# XMC1300 register map
Vendor: Infineon; File version: 1.3.0 (Reference Manual v1.3)
CPU: CM0 r0p0, little endian, no MPU, no FPU, 2 interrupt priority bits
Registers are 32-bit, read-write, reset 0x0 unless marked. A register's access mark holds for its fields unless they carry their own. Offsets are from the block's base; [hi:lo] are bit positions; {n}, {i} and the like mark numbered series.

## ERU0 — Event Request Unit 0
Base 0x40010600
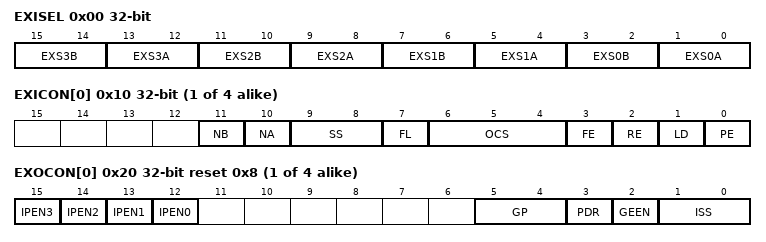
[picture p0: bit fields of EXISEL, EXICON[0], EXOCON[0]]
0x00 EXISEL — Event Input Select
  [4n+3:4n+2] EXS{n}B (n=0..3) — Event Source Select for B{n} (ERS{n})
    {v}=Input ERU_{n}B{v} is selected (v=0..3)
  [4n+1:4n] EXS{n}A (n=0..3) — Event Source Select for A{n} (ERS{n})
    {v}=Input ERU_{n}A{v} is selected (v=0..3)
{0x10+4i} EXICON[{i}] (i=0..3) — Event Input Control
  [11] NB — Input B Negation Select for ERSx
    0=Input B is used directly; 1=Input B is inverted
  [10] NA — Input A Negation Select for ERSx
    0=Input A is used directly; 1=Input A is inverted
  [9:8] SS — Input Source Select for ERSx
    0=Input A without additional combination; 1=Input B without additional combination; 2=Input A OR input B; 3=Input A AND input B
  [7] FL — Status Flag for ETLx
    0=The enabled edge event has not been detected; 1=The enabled edge event has been detected
  [6:4] OCS — Output Channel Select for ETLx Output Trigger Pulse
    {v}=Trigger pulses are sent to OGU{v} (v=0..3)
  [3] FE — Falling Edge Detection Enable ETLx
    0=A falling edge is not considered as edge event; 1=A falling edge is considered as edge event
  [2] RE — Rising Edge Detection Enable ETLx
    0=A rising edge is not considered as edge event; 1=A rising edge is considered as edge event
  [1] LD — Rebuild Level Detection for Status Flag for ETLx
    0=The status flag FL is not cleared by hardware and is used as "sticky" bit. Once set, it is not influenced by any edge until it becomes cleared by software.; 1=The status flag FL rebuilds a level detection of the desired event. It becomes automatically set with a rising edge if RE = 1 or with a falling edge if FE = 1. It becomes automatically cleared with a rising edge if RE = 0 or with a falling edge if FE = 0.
  [0] PE — Output Trigger Pulse Enable for ETLx
    0=The trigger pulse generation is disabled; 1=The trigger pulse generation is enabled
{0x20+4i} EXOCON[{i}] (i=0..3) access per field reset 0x8 — Event Output Trigger Control
  [n+12] IPEN{n} rw (n=0..3) — Pattern Detection Enable for ETL{n}
    0=Flag EXICONx.FL is excluded from the pattern detection; 1=Flag EXICONx.FL is included in the pattern detection
  [5:4] GP rw — Gating Selection for Pattern Detection Result
    0=ERU_GOUTy is always disabled and ERU_IOUTy can not be activated; 1=ERU_GOUTy is always enabled and ERU_IOUTy becomes activated with each activation of ERU_TOUTy; 2=ERU_GOUTy is equal to ERU_PDOUTy and ERU_IOUTy becomes activated with an activation of ERU_TOUTy while the desired pattern is detected (pattern match PDR = 1); 3=ERU_GOUTy is inverted to ERU_PDOUTy and ERU_IOUTy becomes activated with an activation of ERU_TOUTy while the desired pattern is not detected (pattern miss PDR = 0)
  [3] PDR ro — Pattern Detection Result Flag
    0=A pattern miss is detected; 1=A pattern match is detected
  [2] GEEN rw — Gating Event Enable
    0=The event detection is disabled; 1=The event detection is enabled
  [1:0] ISS rw — Internal Trigger Source Selection
    0=The peripheral trigger function is disabled; 1=Input ERU_OGUy1 is selected; 2=Input ERU_OGUy2 is selected; 3=Input ERU_OGUy3 is selected

## NVM — NVM Unit
Base 0x40050000
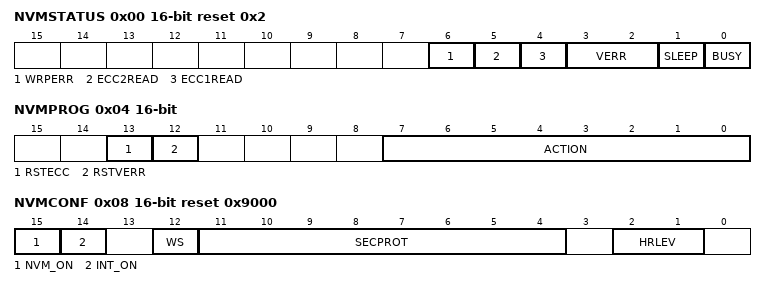
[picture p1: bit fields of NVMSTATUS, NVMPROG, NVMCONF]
0x00 NVMSTATUS 16-bit ro reset 0x2
  [6] WRPERR — Write Protocol Error
    0=No write protocol failure occurred; 1=At least one write protocol failure was detected
  [5] ECC2READ
    0=No ECC two bit failure during memory read operations; 1=At least one ECC two bit failure was detected
  [4] ECC1READ
    0=No ECC single bit failure occurred; 1=At least one ECC single bit failure was detected and corrected
  [3:2] VERR — Verify Error
    0=No fail bit; 1=One fail bit in one data block; 2=Two fail bits in two different data blocks; 3=Two or more fail bits in one data block, or three or more fail bits overall
  [1] SLEEP — Sleep Mode
    0=NVM not in sleep mode, and no sleep or wake up procedure in progress; 1=NVM in sleep mode, or busy due to a sleep or wake up procedure
  [0] BUSY
    0=The NVM is not busy. Memory reads from the cell array and register write accesses are possible.; 1=The NVM is busy. Memory reads and register write accesses are not possible.
0x04 NVMPROG 16-bit — NVM Programming Control Register
  [13] RSTECC — Reset ECC
    0=No action; 1=Reset of .ECCxREAD and NVMSTATUS.WRPERR
  [12] RSTVERR — Reset Verify Error
    0=No action; 1=Reset of .VERR
  [7:0] ACTION — ACTION: [VERIFY, ONE_SHOT, OPTYPE]
    0=Idle state, no action triggered. Writing 0x00 exits current mode.; 81=Start one-shot write operation with automatic verify; 145=Start one-shot write operation without verify; 97=Start continuous write operation with automatic verify of every write; 161=Start continuous write operation without verify; 146=Start one-shot page erase operation; 162=Start continuous page erase operation; 208=Start one-shot verify-only: Written data is compared to array content; 224=Start continuous verify-only: Written data is compared to array content
0x08 NVMCONF 16-bit reset 0x9000 — NVM Configuration Register
  [15] NVM_ON
    0=NVM is switched to or stays in sleep mode; 1=NVM is switched to or stays in normal mode
  [14] INT_ON — Interrupt On
    0=No NVM ready interrupts are generated; 1=NVM ready interrupts are generated
  [12] WS — Number of fixed Wait States
    0=0 fixed wait states; 1=1 fixed wait state
  [11:4] SECPROT — Sector Protection
  [2:1] HRLEV — Hardread Level
    0=Normal read; 1=Hardread written; 2=Hardread erased
0x48 CONFIG1 16-bit reset not defined — Configuration 1 Register
  [11] FIXWS — Wait States Scheme
    0=Const_0 (adaptive wait states.); 1=Const_1 (fixed wait states.)
